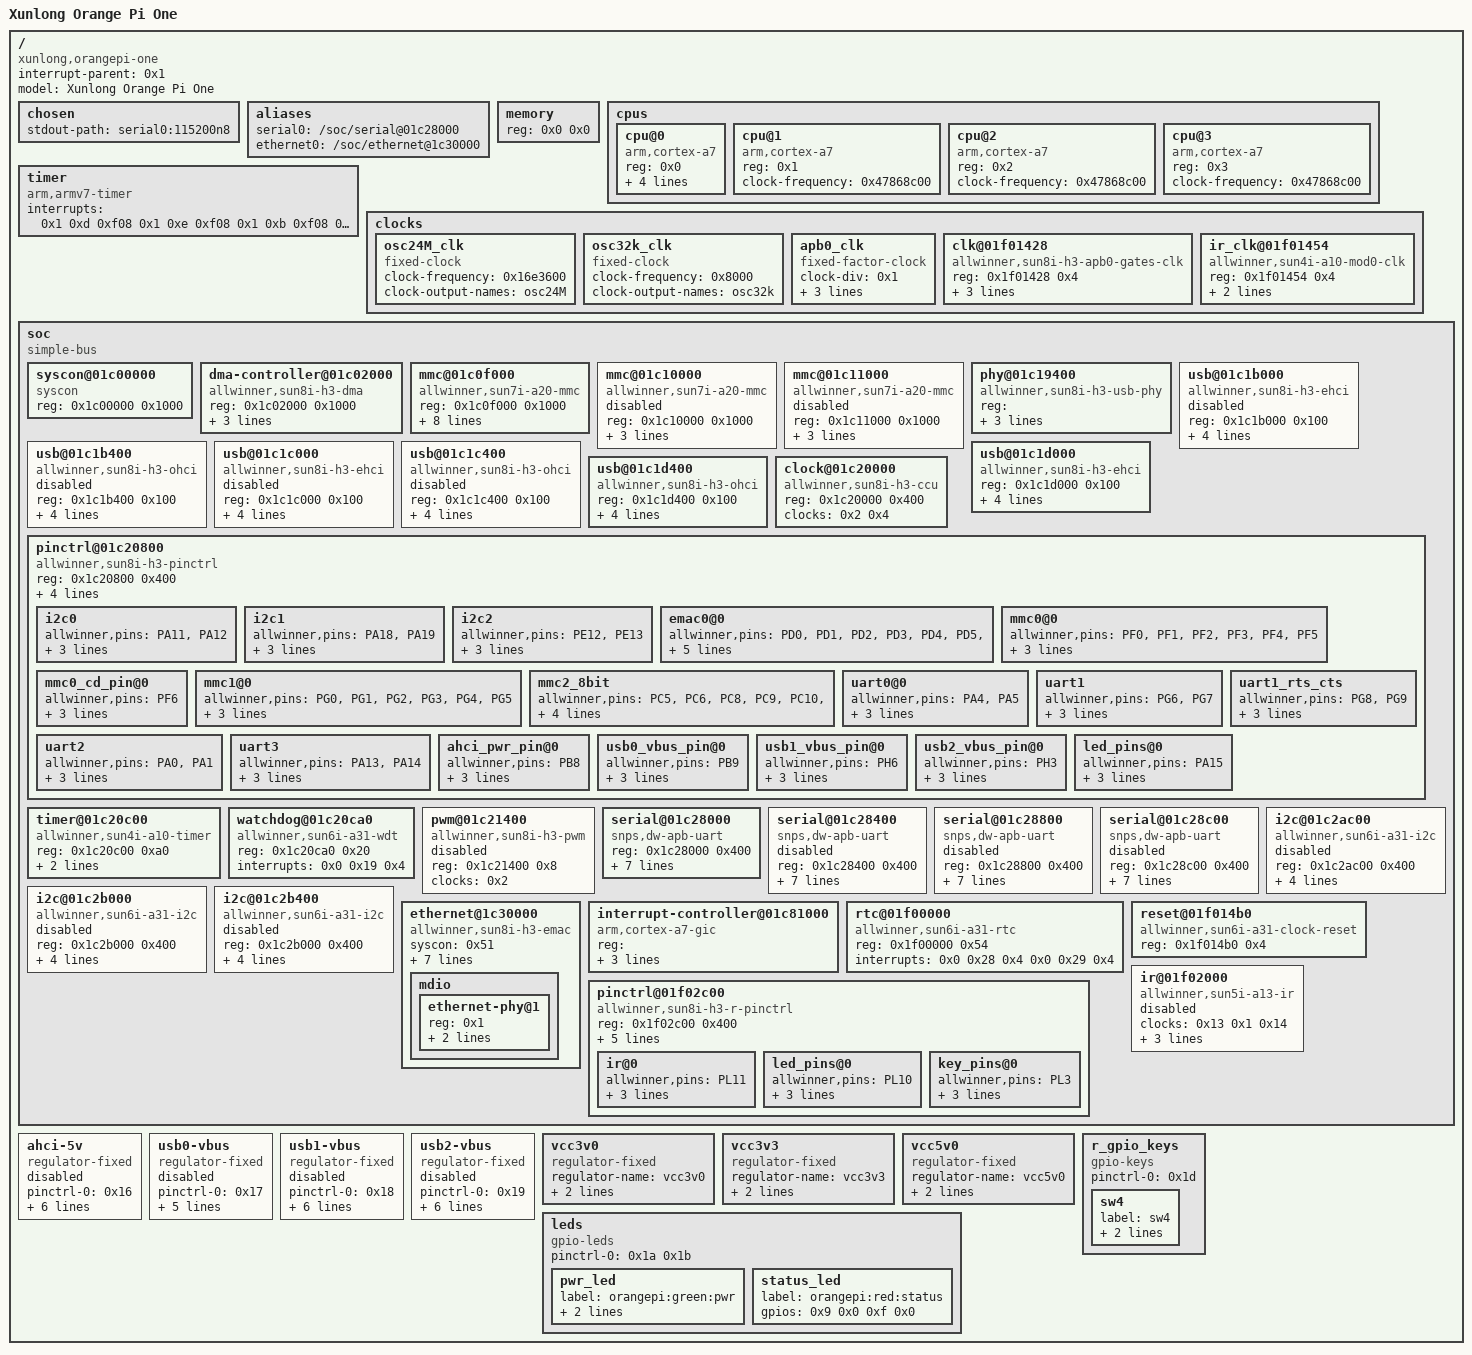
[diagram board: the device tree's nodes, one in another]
/dts-v1/;

/ {
	#address-cells = <0x1>;
	#size-cells = <0x1>;
	interrupt-parent = <0x1>;
	model = "Xunlong Orange Pi One";
	compatible = "xunlong,orangepi-one", "allwinner,sun8i-h3";

	chosen {
		stdout-path = "serial0:115200n8";
	};

	aliases {
		serial0 = "/soc/serial@01c28000";
		ethernet0 = "/soc/ethernet@1c30000";
	};

	memory {
		device_type = "memory";
		reg = <0x0 0x0>;
	};

	cpus {
		#address-cells = <0x1>;
		#size-cells = <0x0>;

		cpu@0 {
			compatible = "arm,cortex-a7";
			device_type = "cpu";
			reg = <0x0>;
			clock-latency = <0x3b9b0>;
			clock-frequency = <0x47868c00>;
			operating-points = <0x124f80 0x13d620 0xf6180 0x13d620 0xc7380 0x10c8e0 0x98580 0x10c8e0 0x75300 0x10c8e0 0x4c2c0 0x10c8e0 0x3a980 0x10c8e0 0x1d4c0 0x10c8e0>;
		};

		cpu@1 {
			compatible = "arm,cortex-a7";
			device_type = "cpu";
			reg = <0x1>;
			clock-frequency = <0x47868c00>;
		};

		cpu@2 {
			compatible = "arm,cortex-a7";
			device_type = "cpu";
			reg = <0x2>;
			clock-frequency = <0x47868c00>;
		};

		cpu@3 {
			compatible = "arm,cortex-a7";
			device_type = "cpu";
			reg = <0x3>;
			clock-frequency = <0x47868c00>;
		};
	};

	timer {
		compatible = "arm,armv7-timer";
		interrupts = <0x1 0xd 0xf08 0x1 0xe 0xf08 0x1 0xb 0xf08 0x1 0xa 0xf08>;
	};

	clocks {
		#address-cells = <0x1>;
		#size-cells = <0x1>;
		ranges;

		osc24M_clk {
			#clock-cells = <0x0>;
			compatible = "fixed-clock";
			clock-frequency = <0x16e3600>;
			clock-output-names = "osc24M";
			linux,phandle = <0x2>;
			phandle = <0x2>;
		};

		osc32k_clk {
			#clock-cells = <0x0>;
			compatible = "fixed-clock";
			clock-frequency = <0x8000>;
			clock-output-names = "osc32k";
			linux,phandle = <0x4>;
			phandle = <0x4>;
		};

		apb0_clk {
			compatible = "fixed-factor-clock";
			#clock-cells = <0x0>;
			clock-div = <0x1>;
			clock-mult = <0x1>;
			clocks = <0x2>;
			clock-output-names = "apb0";
			linux,phandle = <0x3>;
			phandle = <0x3>;
		};

		clk@01f01428 {
			compatible = "allwinner,sun8i-h3-apb0-gates-clk", "allwinner,sun4i-a10-gates-clk";
			reg = <0x1f01428 0x4>;
			#clock-cells = <0x1>;
			clocks = <0x3>;
			clock-indices = <0x0 0x1>;
			clock-output-names = "apb0_pio", "apb0_ir";
			linux,phandle = <0x13>;
			phandle = <0x13>;
		};

		ir_clk@01f01454 {
			compatible = "allwinner,sun4i-a10-mod0-clk";
			reg = <0x1f01454 0x4>;
			#clock-cells = <0x0>;
			clocks = <0x4 0x2>;
			clock-output-names = "ir";
			linux,phandle = <0x14>;
			phandle = <0x14>;
		};
	};

	soc {
		compatible = "simple-bus";
		#address-cells = <0x1>;
		#size-cells = <0x1>;
		ranges;

		syscon@01c00000 {
			compatible = "syscon", "allwinner,sun8i-h3-system-controller";
			reg = <0x1c00000 0x1000>;
			linux,phandle = <0x51>;
			phandle = <0x51>;
		};

		dma-controller@01c02000 {
			compatible = "allwinner,sun8i-h3-dma";
			reg = <0x1c02000 0x1000>;
			interrupts = <0x0 0x32 0x4>;
			clocks = <0x5 0x15>;
			resets = <0x5 0x6>;
			#dma-cells = <0x1>;
			linux,phandle = <0xb>;
			phandle = <0xb>;
		};

		mmc@01c0f000 {
			compatible = "allwinner,sun7i-a20-mmc";
			reg = <0x1c0f000 0x1000>;
			clocks = <0x5 0x16 0x5 0x47 0x5 0x49 0x5 0x48>;
			clock-names = "ahb", "mmc", "output", "sample";
			resets = <0x5 0x7>;
			reset-names = "ahb";
			interrupts = <0x0 0x3c 0x4>;
			status = "okay";
			#address-cells = <0x1>;
			#size-cells = <0x0>;
			pinctrl-names = "default";
			pinctrl-0 = <0x6 0x7>;
			vmmc-supply = <0x8>;
			bus-width = <0x4>;
			cd-gpios = <0x9 0x5 0x6 0x0>;
			cd-inverted;
		};

		mmc@01c10000 {
			compatible = "allwinner,sun7i-a20-mmc";
			reg = <0x1c10000 0x1000>;
			clocks = <0x5 0x17 0x5 0x4a 0x5 0x4c 0x5 0x4b>;
			clock-names = "ahb", "mmc", "output", "sample";
			resets = <0x5 0x8>;
			reset-names = "ahb";
			interrupts = <0x0 0x3d 0x4>;
			status = "disabled";
			#address-cells = <0x1>;
			#size-cells = <0x0>;
		};

		mmc@01c11000 {
			compatible = "allwinner,sun7i-a20-mmc";
			reg = <0x1c11000 0x1000>;
			clocks = <0x5 0x18 0x5 0x4d 0x5 0x4f 0x5 0x4e>;
			clock-names = "ahb", "mmc", "output", "sample";
			resets = <0x5 0x9>;
			reset-names = "ahb";
			interrupts = <0x0 0x3e 0x4>;
			status = "disabled";
			#address-cells = <0x1>;
			#size-cells = <0x0>;
		};

		phy@01c19400 {
			compatible = "allwinner,sun8i-h3-usb-phy";
			reg = <0x1c19400 0x2c 0x1c1a800 0x4 0x1c1b800 0x4 0x1c1c800 0x4 0x1c1d800 0x4>;
			reg-names = "phy_ctrl", "pmu0", "pmu1", "pmu2", "pmu3";
			clocks = <0x5 0x58 0x5 0x59 0x5 0x5a 0x5 0x5b>;
			clock-names = "usb0_phy", "usb1_phy", "usb2_phy", "usb3_phy";
			resets = <0x5 0x0 0x5 0x1 0x5 0x2 0x5 0x3>;
			reset-names = "usb0_reset", "usb1_reset", "usb2_reset", "usb3_reset";
			status = "okay";
			#phy-cells = <0x1>;
			linux,phandle = <0xa>;
			phandle = <0xa>;
		};

		usb@01c1b000 {
			compatible = "allwinner,sun8i-h3-ehci", "generic-ehci";
			reg = <0x1c1b000 0x100>;
			interrupts = <0x0 0x4a 0x4>;
			clocks = <0x5 0x22 0x5 0x26>;
			resets = <0x5 0x13 0x5 0x17>;
			phys = <0xa 0x1>;
			phy-names = "usb";
			status = "disabled";
		};

		usb@01c1b400 {
			compatible = "allwinner,sun8i-h3-ohci", "generic-ohci";
			reg = <0x1c1b400 0x100>;
			interrupts = <0x0 0x4b 0x4>;
			clocks = <0x5 0x22 0x5 0x26 0x5 0x5d>;
			resets = <0x5 0x13 0x5 0x17>;
			phys = <0xa 0x1>;
			phy-names = "usb";
			status = "disabled";
		};

		usb@01c1c000 {
			compatible = "allwinner,sun8i-h3-ehci", "generic-ehci";
			reg = <0x1c1c000 0x100>;
			interrupts = <0x0 0x4c 0x4>;
			clocks = <0x5 0x23 0x5 0x27>;
			resets = <0x5 0x14 0x5 0x18>;
			phys = <0xa 0x2>;
			phy-names = "usb";
			status = "disabled";
		};

		usb@01c1c400 {
			compatible = "allwinner,sun8i-h3-ohci", "generic-ohci";
			reg = <0x1c1c400 0x100>;
			interrupts = <0x0 0x4d 0x4>;
			clocks = <0x5 0x23 0x5 0x27 0x5 0x5e>;
			resets = <0x5 0x14 0x5 0x18>;
			phys = <0xa 0x2>;
			phy-names = "usb";
			status = "disabled";
		};

		usb@01c1d000 {
			compatible = "allwinner,sun8i-h3-ehci", "generic-ehci";
			reg = <0x1c1d000 0x100>;
			interrupts = <0x0 0x4e 0x4>;
			clocks = <0x5 0x24 0x5 0x28>;
			resets = <0x5 0x15 0x5 0x19>;
			phys = <0xa 0x3>;
			phy-names = "usb";
			status = "okay";
		};

		usb@01c1d400 {
			compatible = "allwinner,sun8i-h3-ohci", "generic-ohci";
			reg = <0x1c1d400 0x100>;
			interrupts = <0x0 0x4f 0x4>;
			clocks = <0x5 0x24 0x5 0x28 0x5 0x5f>;
			resets = <0x5 0x15 0x5 0x19>;
			phys = <0xa 0x3>;
			phy-names = "usb";
			status = "okay";
		};

		clock@01c20000 {
			compatible = "allwinner,sun8i-h3-ccu";
			reg = <0x1c20000 0x400>;
			clocks = <0x2 0x4>;
			clock-names = "hosc", "losc";
			#clock-cells = <0x1>;
			#reset-cells = <0x1>;
			linux,phandle = <0x5>;
			phandle = <0x5>;
		};

		pinctrl@01c20800 {
			compatible = "allwinner,sun8i-h3-pinctrl";
			reg = <0x1c20800 0x400>;
			interrupts = <0x0 0xb 0x4 0x0 0x11 0x4>;
			clocks = <0x5 0x36>;
			gpio-controller;
			#gpio-cells = <0x3>;
			interrupt-controller;
			#interrupt-cells = <0x3>;
			linux,phandle = <0x9>;
			phandle = <0x9>;

			i2c0 {
				allwinner,pins = "PA11", "PA12";
				allwinner,function = "i2c0";
				allwinner,drive = <0x0>;
				allwinner,pull = <0x0>;
				linux,phandle = <0x10>;
				phandle = <0x10>;
			};

			i2c1 {
				allwinner,pins = "PA18", "PA19";
				allwinner,function = "i2c1";
				allwinner,drive = <0x0>;
				allwinner,pull = <0x0>;
				linux,phandle = <0x11>;
				phandle = <0x11>;
			};

			i2c2 {
				allwinner,pins = "PE12", "PE13";
				allwinner,function = "i2c2";
				allwinner,drive = <0x0>;
				allwinner,pull = <0x0>;
				linux,phandle = <0x12>;
				phandle = <0x12>;
			};

			emac0@0 {
				allwinner,pins = "PD0", "PD1", "PD2", "PD3", "PD4", "PD5", "PD7", "PD8", "PD9", "PD10", "PD12", "PD13", "PD15", "PD16", "PD17";
				allwinner,function = "emac";
				allwinner,drive = <0x2>;
				allwinner,pull = <0x0>;
			};

			mmc0@0 {
				allwinner,pins = "PF0", "PF1", "PF2", "PF3", "PF4", "PF5";
				allwinner,function = "mmc0";
				allwinner,drive = <0x2>;
				allwinner,pull = <0x0>;
				linux,phandle = <0x6>;
				phandle = <0x6>;
			};

			mmc0_cd_pin@0 {
				allwinner,pins = "PF6";
				allwinner,function = "gpio_in";
				allwinner,drive = <0x0>;
				allwinner,pull = <0x1>;
				linux,phandle = <0x7>;
				phandle = <0x7>;
			};

			mmc1@0 {
				allwinner,pins = "PG0", "PG1", "PG2", "PG3", "PG4", "PG5";
				allwinner,function = "mmc1";
				allwinner,drive = <0x2>;
				allwinner,pull = <0x0>;
			};

			mmc2_8bit {
				allwinner,pins = "PC5", "PC6", "PC8", "PC9", "PC10", "PC11", "PC12", "PC13", "PC14", "PC15", "PC16";
				allwinner,function = "mmc2";
				allwinner,drive = <0x2>;
				allwinner,pull = <0x0>;
			};

			uart0@0 {
				allwinner,pins = "PA4", "PA5";
				allwinner,function = "uart0";
				allwinner,drive = <0x0>;
				allwinner,pull = <0x0>;
				linux,phandle = <0xc>;
				phandle = <0xc>;
			};

			uart1 {
				allwinner,pins = "PG6", "PG7";
				allwinner,function = "uart1";
				allwinner,drive = <0x0>;
				allwinner,pull = <0x0>;
				linux,phandle = <0xd>;
				phandle = <0xd>;
			};

			uart1_rts_cts {
				allwinner,pins = "PG8", "PG9";
				allwinner,function = "uart1";
				allwinner,drive = <0x0>;
				allwinner,pull = <0x0>;
			};

			uart2 {
				allwinner,pins = "PA0", "PA1";
				allwinner,function = "uart2";
				allwinner,drive = <0x0>;
				allwinner,pull = <0x0>;
				linux,phandle = <0xe>;
				phandle = <0xe>;
			};

			uart3 {
				allwinner,pins = "PA13", "PA14";
				allwinner,function = "uart3";
				allwinner,drive = <0x0>;
				allwinner,pull = <0x0>;
				linux,phandle = <0xf>;
				phandle = <0xf>;
			};

			ahci_pwr_pin@0 {
				allwinner,pins = "PB8";
				allwinner,function = "gpio_out";
				allwinner,drive = <0x0>;
				allwinner,pull = <0x0>;
				linux,phandle = <0x16>;
				phandle = <0x16>;
			};

			usb0_vbus_pin@0 {
				allwinner,pins = "PB9";
				allwinner,function = "gpio_out";
				allwinner,drive = <0x0>;
				allwinner,pull = <0x0>;
				linux,phandle = <0x17>;
				phandle = <0x17>;
			};

			usb1_vbus_pin@0 {
				allwinner,pins = "PH6";
				allwinner,function = "gpio_out";
				allwinner,drive = <0x0>;
				allwinner,pull = <0x0>;
				linux,phandle = <0x18>;
				phandle = <0x18>;
			};

			usb2_vbus_pin@0 {
				allwinner,pins = "PH3";
				allwinner,function = "gpio_out";
				allwinner,drive = <0x0>;
				allwinner,pull = <0x0>;
				linux,phandle = <0x19>;
				phandle = <0x19>;
			};

			led_pins@0 {
				allwinner,pins = "PA15";
				allwinner,function = "gpio_out";
				allwinner,drive = <0x0>;
				allwinner,pull = <0x0>;
				linux,phandle = <0x1a>;
				phandle = <0x1a>;
			};
		};

		timer@01c20c00 {
			compatible = "allwinner,sun4i-a10-timer";
			reg = <0x1c20c00 0xa0>;
			interrupts = <0x0 0x12 0x4 0x0 0x13 0x4>;
			clocks = <0x2>;
		};

		watchdog@01c20ca0 {
			compatible = "allwinner,sun6i-a31-wdt";
			reg = <0x1c20ca0 0x20>;
			interrupts = <0x0 0x19 0x4>;
		};

		pwm@01c21400 {
			compatible = "allwinner,sun8i-h3-pwm";
			reg = <0x1c21400 0x8>;
			clocks = <0x2>;
			#pwm-cells = <0x3>;
			status = "disabled";
		};

		serial@01c28000 {
			compatible = "snps,dw-apb-uart";
			reg = <0x1c28000 0x400>;
			interrupts = <0x0 0x0 0x4>;
			reg-shift = <0x2>;
			reg-io-width = <0x4>;
			clocks = <0x5 0x3e>;
			resets = <0x5 0x31>;
			dmas = <0xb 0x6 0xb 0x6>;
			dma-names = "rx", "tx";
			status = "okay";
			pinctrl-names = "default";
			pinctrl-0 = <0xc>;
		};

		serial@01c28400 {
			compatible = "snps,dw-apb-uart";
			reg = <0x1c28400 0x400>;
			interrupts = <0x0 0x1 0x4>;
			reg-shift = <0x2>;
			reg-io-width = <0x4>;
			clocks = <0x5 0x3f>;
			resets = <0x5 0x32>;
			dmas = <0xb 0x7 0xb 0x7>;
			dma-names = "rx", "tx";
			status = "disabled";
			pinctrl-names = "default";
			pinctrl-0 = <0xd>;
		};

		serial@01c28800 {
			compatible = "snps,dw-apb-uart";
			reg = <0x1c28800 0x400>;
			interrupts = <0x0 0x2 0x4>;
			reg-shift = <0x2>;
			reg-io-width = <0x4>;
			clocks = <0x5 0x40>;
			resets = <0x5 0x33>;
			dmas = <0xb 0x8 0xb 0x8>;
			dma-names = "rx", "tx";
			status = "disabled";
			pinctrl-names = "default";
			pinctrl-0 = <0xe>;
		};

		serial@01c28c00 {
			compatible = "snps,dw-apb-uart";
			reg = <0x1c28c00 0x400>;
			interrupts = <0x0 0x3 0x4>;
			reg-shift = <0x2>;
			reg-io-width = <0x4>;
			clocks = <0x5 0x41>;
			resets = <0x5 0x34>;
			dmas = <0xb 0x9 0xb 0x9>;
			dma-names = "rx", "tx";
			status = "disabled";
			pinctrl-names = "default";
			pinctrl-0 = <0xf>;
		};

		i2c@01c2ac00 {
			compatible = "allwinner,sun6i-a31-i2c";
			reg = <0x1c2ac00 0x400>;
			interrupts = <0x0 0x6 0x4>;
			clocks = <0x5 0x3b>;
			resets = <0x5 0x2e>;
			pinctrl-names = "default";
			pinctrl-0 = <0x10>;
			status = "disabled";
			#address-cells = <0x1>;
			#size-cells = <0x0>;
		};

		i2c@01c2b000 {
			compatible = "allwinner,sun6i-a31-i2c";
			reg = <0x1c2b000 0x400>;
			interrupts = <0x0 0x7 0x4>;
			clocks = <0x5 0x3c>;
			resets = <0x5 0x2f>;
			pinctrl-names = "default";
			pinctrl-0 = <0x11>;
			status = "disabled";
			#address-cells = <0x1>;
			#size-cells = <0x0>;
		};

		i2c@01c2b400 {
			compatible = "allwinner,sun6i-a31-i2c";
			reg = <0x1c2b000 0x400>;
			interrupts = <0x0 0x8 0x4>;
			clocks = <0x5 0x3d>;
			resets = <0x5 0x30>;
			pinctrl-names = "default";
			pinctrl-0 = <0x12>;
			status = "disabled";
			#address-cells = <0x1>;
			#size-cells = <0x0>;
		};

		ethernet@1c30000 {
			compatible = "allwinner,sun8i-h3-emac";
			syscon = <0x51>;
			reg = <0x1c30000 0x104>;
			interrupts = <0x0 0x52 0x4>;
			resets = <0x5 0xc>;
			reset-names = "ahb";
			clocks = <0x5 0x1b>;
			clock-names = "ahb";
			#address-cells = <0x1>;
			#size-cells = <0x0>;
			status = "okay";
			phy-handle = <0x50>;
			phy-mode = "mii";
			allwinner,leds-active-low;

			mdio {
				#address-cells = <0x1>;
				#size-cells = <0x0>;

				ethernet-phy@1 {
					reg = <0x1>;
					clocks = <0x5 0x43>;
					resets = <0x5 0x27>;
					linux,phandle = <0x50>;
					phandle = <0x50>;
				};
			};
		};

		interrupt-controller@01c81000 {
			compatible = "arm,cortex-a7-gic", "arm,cortex-a15-gic";
			reg = <0x1c81000 0x1000 0x1c82000 0x1000 0x1c84000 0x2000 0x1c86000 0x2000>;
			interrupt-controller;
			#interrupt-cells = <0x3>;
			interrupts = <0x1 0x9 0xf04>;
			linux,phandle = <0x1>;
			phandle = <0x1>;
		};

		rtc@01f00000 {
			compatible = "allwinner,sun6i-a31-rtc";
			reg = <0x1f00000 0x54>;
			interrupts = <0x0 0x28 0x4 0x0 0x29 0x4>;
		};

		reset@01f014b0 {
			reg = <0x1f014b0 0x4>;
			compatible = "allwinner,sun6i-a31-clock-reset";
			#reset-cells = <0x1>;
			linux,phandle = <0x15>;
			phandle = <0x15>;
		};

		ir@01f02000 {
			compatible = "allwinner,sun5i-a13-ir";
			clocks = <0x13 0x1 0x14>;
			clock-names = "apb", "ir";
			resets = <0x15 0x1>;
			interrupts = <0x0 0x25 0x4>;
			reg = <0x1f02000 0x40>;
			status = "disabled";
		};

		pinctrl@01f02c00 {
			compatible = "allwinner,sun8i-h3-r-pinctrl";
			reg = <0x1f02c00 0x400>;
			interrupts = <0x0 0x2d 0x4>;
			clocks = <0x13 0x0>;
			resets = <0x15 0x0>;
			gpio-controller;
			#gpio-cells = <0x3>;
			interrupt-controller;
			#interrupt-cells = <0x3>;
			linux,phandle = <0x1c>;
			phandle = <0x1c>;

			ir@0 {
				allwinner,pins = "PL11";
				allwinner,function = "s_cir_rx";
				allwinner,drive = <0x0>;
				allwinner,pull = <0x0>;
			};

			led_pins@0 {
				allwinner,pins = "PL10";
				allwinner,function = "gpio_out";
				allwinner,drive = <0x0>;
				allwinner,pull = <0x0>;
				linux,phandle = <0x1b>;
				phandle = <0x1b>;
			};

			key_pins@0 {
				allwinner,pins = "PL3";
				allwinner,function = "gpio_in";
				allwinner,drive = <0x0>;
				allwinner,pull = <0x0>;
				linux,phandle = <0x1d>;
				phandle = <0x1d>;
			};
		};
	};

	ahci-5v {
		compatible = "regulator-fixed";
		pinctrl-names = "default";
		pinctrl-0 = <0x16>;
		regulator-name = "ahci-5v";
		regulator-min-microvolt = <0x4c4b40>;
		regulator-max-microvolt = <0x4c4b40>;
		regulator-boot-on;
		enable-active-high;
		gpio = <0x9 0x1 0x8 0x0>;
		status = "disabled";
	};

	usb0-vbus {
		compatible = "regulator-fixed";
		pinctrl-names = "default";
		pinctrl-0 = <0x17>;
		regulator-name = "usb0-vbus";
		regulator-min-microvolt = <0x4c4b40>;
		regulator-max-microvolt = <0x4c4b40>;
		enable-active-high;
		gpio = <0x9 0x1 0x9 0x0>;
		status = "disabled";
	};

	usb1-vbus {
		compatible = "regulator-fixed";
		pinctrl-names = "default";
		pinctrl-0 = <0x18>;
		regulator-name = "usb1-vbus";
		regulator-min-microvolt = <0x4c4b40>;
		regulator-max-microvolt = <0x4c4b40>;
		regulator-boot-on;
		enable-active-high;
		gpio = <0x9 0x7 0x6 0x0>;
		status = "disabled";
	};

	usb2-vbus {
		compatible = "regulator-fixed";
		pinctrl-names = "default";
		pinctrl-0 = <0x19>;
		regulator-name = "usb2-vbus";
		regulator-min-microvolt = <0x4c4b40>;
		regulator-max-microvolt = <0x4c4b40>;
		regulator-boot-on;
		enable-active-high;
		gpio = <0x9 0x7 0x3 0x0>;
		status = "disabled";
	};

	vcc3v0 {
		compatible = "regulator-fixed";
		regulator-name = "vcc3v0";
		regulator-min-microvolt = <0x2dc6c0>;
		regulator-max-microvolt = <0x2dc6c0>;
	};

	vcc3v3 {
		compatible = "regulator-fixed";
		regulator-name = "vcc3v3";
		regulator-min-microvolt = <0x325aa0>;
		regulator-max-microvolt = <0x325aa0>;
		linux,phandle = <0x8>;
		phandle = <0x8>;
	};

	vcc5v0 {
		compatible = "regulator-fixed";
		regulator-name = "vcc5v0";
		regulator-min-microvolt = <0x4c4b40>;
		regulator-max-microvolt = <0x4c4b40>;
	};

	leds {
		compatible = "gpio-leds";
		pinctrl-names = "default";
		pinctrl-0 = <0x1a 0x1b>;

		pwr_led {
			label = "orangepi:green:pwr";
			gpios = <0x1c 0x0 0xa 0x0>;
			default-state = "on";
		};

		status_led {
			label = "orangepi:red:status";
			gpios = <0x9 0x0 0xf 0x0>;
		};
	};

	r_gpio_keys {
		compatible = "gpio-keys";
		pinctrl-names = "default";
		pinctrl-0 = <0x1d>;

		sw4 {
			label = "sw4";
			linux,code = <0x100>;
			gpios = <0x1c 0x0 0x3 0x1>;
		};
	};
};

